AUTOSAR XML (schema 4-2-2)
standard types defined: sint32, boolean, Boolean
package /BwXev
  app type SysState_pwrModeStateEnumType: category=VALUE, sw-calibration-access=READ-WRITE, compu {0=SysState_pwrModeStateEnumType_Startup, 1=SysState_pwrModeStateEnumType_Run, 2=SysState_pwrModeStateEnumType_PostRun, 3=SysState_pwrModeStateEnumType_Shutdown}
  data type mapping set SysCtrlDataTypeMappingsSet
    data-type-maps:
      application-data-type=SysState_pwrModeStateEnumType, implementation-data-type=SysState_pwrModeStateEnumType
      application-data-type=SysState_emCddStateEnumType, implementation-data-type=SysState_emCddStateEnumType
      application-data-type=SysState_sysCtrlStateEnumType, implementation-data-type=SysState_sysCtrlStateEnumType
  unit NoUnit: factor-si-to-unit=1, offset-si-to-unit=0
  app type SysState_emCddStateEnumType: category=VALUE, sw-calibration-access=READ-WRITE, compu {0=SysState_emCddStateEnumType_Startup, 1=SysState_emCddStateEnumType_Initialize, 2=SysState_emCddStateEnumType_Standby, 3=SysState_emCddStateEnumType_Run, 4=SysState_emCddStateEnumType_Fault, 5=SysState_emCddStateEnumType_PostRun, 6=SysState_emCddStateEnumType_Shutdown}
  compu method COMPU_Boolean: 0=FALSE, 1=TRUE
  app type SysState_sysCtrlStateEnumType: category=VALUE, sw-calibration-access=READ-WRITE, compu {0=SysState_sysCtrlStateEnumType_Startup, 1=SysState_sysCtrlStateEnumType_Initialize, 2=SysState_sysCtrlStateEnumType_Run, 3=SysState_sysCtrlStateEnumType_PostRun, 4=SysState_sysCtrlStateEnumType_Shutdown}
package /BwXev/Components
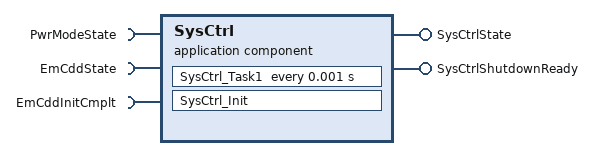
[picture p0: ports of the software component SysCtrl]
  application sw component type SysCtrl
    require port PwrModeState: nonqueued-receiver-com-spec{data-element=PwrModeState, init-value=SysState_pwrModeStateEnumType_Startup}, required-interface=PwrModeState
    require port EmCddState: nonqueued-receiver-com-spec{data-element=EmCddState, init-value=SysState_emCddStateEnumType_Startup}, required-interface=EmCddState
    require port EmCddInitCmplt: nonqueued-receiver-com-spec{data-element=EmCddInitCmplt, init-value=0}, required-interface=EmCddInitCmplt
    provide port SysCtrlState: nonqueued-sender-com-spec{data-element=SysCtrlState, init-value=SysState_sysCtrlStateEnumType_Startup}, provided-interface=SysCtrlState
    provide port SysCtrlShutdownReady: nonqueued-sender-com-spec{data-element=SysCtrlShutdownReady, init-value=0}, provided-interface=SysCtrlShutdownReady
    behavior SysCtrl_IB: data-type-mapping=SysCtrlDataTypeMappingsSet, handle-termination-and-restart=NO-SUPPORT
      timing event Event_SysCtrl_Task1: start-on-event=SysCtrl_Task1, period=0.001
      init event Event_SysCtrlInit: start-on-event=SysCtrl_Init
      runnable SysCtrl_Init: sw-addr-method=CODE_QM_LOCAL
        data-write-access:
          access OUT_SysCtrlState_SysCtrlState: accessed-variable=SysCtrlState.SysCtrlState
          access OUT_SysCtrlShutdownReady_SysCtrlShutdownReady: accessed-variable=SysCtrlShutdownReady.SysCtrlShutdownReady
      runnable SysCtrl_Task1: sw-addr-method=CODE_1MS_QM_LOCAL
        data-read-access:
          access IN_EmCddInitCmplt_EmCddInitCmplt: accessed-variable=EmCddInitCmplt.EmCddInitCmplt
          access IN_EmCddState_EmCddState: accessed-variable=EmCddState.EmCddState
          access IN_PwrModeState_PwrModeState: accessed-variable=PwrModeState.PwrModeState
        data-write-access:
          access OUT_SysCtrlState_SysCtrlState: accessed-variable=SysCtrlState.SysCtrlState
          access OUT_SysCtrlShutdownReady_SysCtrlShutdownReady: accessed-variable=SysCtrlShutdownReady.SysCtrlShutdownReady
package /BwXev/Components/SwcImplementations
  swc implementation SysCtrl_Impl: programming-language=C, sw-version=1.1757.1, used-code-generator=Embedded Coder 7.3 (R2019b) 18-Jul-2019, vendor-id=0, behavior=SysCtrl_IB
    code-descriptors:
      code Code
        artifact-descriptors:
          short-label=SysCtrl_c, category=SWSRC
          short-label=SysStateTask1_c, category=SWSRC
          short-label=SysCtrl_h, category=SWHDR
          short-label=SysStateTask1_h, category=SWHDR
          short-label=SysStateTask1_private_h, category=SWHDR
          short-label=SysStateTask1_types_h, category=SWHDR
          short-label=rtwtypes_h, category=SWHDR
    resource consumption RsrcCons_SysCtrl
package /BwXev/Interfaces
  5 x sender receiver interface:
    PwrModeState
      data PwrModeState: category=VALUE, sw-calibration-access=READ-ONLY, type=SysState_pwrModeStateEnumType
    EmCddState
      data EmCddState: category=VALUE, sw-calibration-access=READ-ONLY, type=SysState_emCddStateEnumType
    EmCddInitCmplt
      data EmCddInitCmplt: category=VALUE, sw-calibration-access=READ-ONLY, type=Boolean
    SysCtrlState
      data SysCtrlState: category=VALUE, sw-calibration-access=READ-ONLY, type=SysState_sysCtrlStateEnumType
    SysCtrlShutdownReady
      data SysCtrlShutdownReady: category=VALUE, sw-calibration-access=READ-ONLY, type=Boolean
package /BwXev/DataTypes
  impl type SysState_pwrModeStateEnumType: category=VALUE, base-type=sint32
  impl type SysState_emCddStateEnumType: category=VALUE, base-type=sint32
  impl type SysState_sysCtrlStateEnumType: category=VALUE, base-type=sint32
package /BwXev/DataTypes/SwAddrMethods
  7 x sw addr method:
    CODE: section-type=CODE
    CONST: section-type=CONST
    VAR: section-type=VAR
    EMCAT1_CODE_FAST_QM_LOCAL: section-type=CODE
    CODE_1MS_QM_LOCAL: memory-allocation-keyword-policy=ADDR-METHOD-SHORT-NAME, section-type=CODE
    CODE_10MS_QM_LOCAL: section-type=CODE
    CODE_QM_LOCAL: memory-allocation-keyword-policy=ADDR-METHOD-SHORT-NAME, section-type=CODE
